# IVAHD_PRM register map
Vendor: Texas Instruments
Peripheral module from a debugger description file (folder omap4430).
Registers are 32-bit, access not given, reset 0xFF0E03 unless marked. A register's access mark holds for its fields unless they carry their own. Offsets are as the file gives them; lines under a group give offsets from that group; [hi:lo] are bit positions; {n}, {i} and the like mark numbered series; 'fields as' and 'values as' point back to an identical list; <NAME> marks a mode.

## IVAHD_PRM
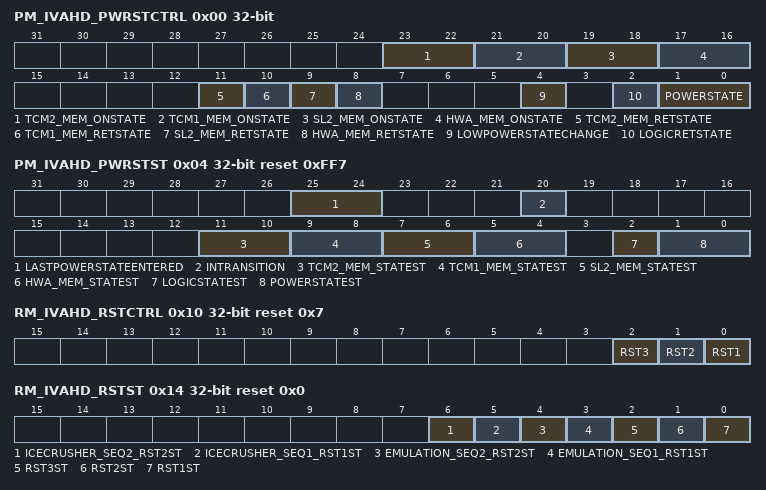
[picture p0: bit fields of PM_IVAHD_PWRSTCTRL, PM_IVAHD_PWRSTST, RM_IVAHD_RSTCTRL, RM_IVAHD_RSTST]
0x00 PM_IVAHD_PWRSTCTRL — This register controls the IVAHD power state to reach upon a domain sleep transition
  [23:22] TCM2_MEM_ONSTATE — TCM2 memory state when domain is ON. (access R Rreturns1s)
    3=TCM2_MEM_ONSTATE_3_r (Memory bank is on when the domain is ON.)
  [21:20] TCM1_MEM_ONSTATE — TCM1 memory state when domain is ON. (access R Rreturns1s)
    3=TCM1_MEM_ONSTATE_3_r (Memory bank is on when the domain is ON.)
  [19:18] SL2_MEM_ONSTATE — SL2 memory state when domain is ON. (access R Rreturns1s)
    3=SL2_MEM_ONSTATE_3_r (Memory bank is on when the domain is ON.)
  [17:16] HWA_MEM_ONSTATE — HWA memory state when domain is ON. (access R Rreturns1s)
    3=HWA_MEM_ONSTATE_3_r (Memory bank is on when the domain is ON.)
  [11] TCM2_MEM_RETSTATE rw — TCM2 memory state when domain is RETENTION.
    0=Memory bank is off when the domain is in the RETENTION state; 1=Memory bank is retained when domain is in RETENTION state
  [10] TCM1_MEM_RETSTATE rw — TCM1 memory state when domain is RETENTION.
    values as TCM2_MEM_RETSTATE
  [9] SL2_MEM_RETSTATE rw — SL2 memory state when domain is RETENTION.
    values as TCM2_MEM_RETSTATE
  [8] HWA_MEM_RETSTATE ro — HWA memory state when domain is RETENTION.
    0=HWA_MEM_RETSTATE_0_r (Memory bank is off when the domain is in the RETENTION state.)
  [4] LOWPOWERSTATECHANGE — Power state change request when domain has already performed a sleep transition. Allows going into deeper low power state without waking up the power domain. (access RW WSpecial)
    0=Do not request a low power state change; 1=Request a low power state change. This bit is automatically cleared when the power state is effectively changed or when power state is ON.
  [2] LOGICRETSTATE ro — Logic state when power domain is RETENTION
    0=LOGICRETSTATE_0_r (Whole logic is off when the domain is in RETENTION state.)
  [1:0] POWERSTATE rw — Power state control
    0=OFF state; 1=RETENTION state; 2=INACTIVE state; 3=ON State
0x04 PM_IVAHD_PWRSTST reset 0xFF7 — This register provides a status on the current IVAHD power domain state. [warm reset insensitive]
  [25:24] LASTPOWERSTATEENTERED — Last low power state entered. Set to 0x3 upon write of the same only. This register is intended for debug purpose only. (access RW W1toSet)
    3=LASTPOWERSTATEENTERED_3_r (Power domain was previously ON-ACTIVE); 2=LASTPOWERSTATEENTERED_2_r (Power domain was previously ON-INACTIVE); 1=LASTPOWERSTATEENTERED_1_r (Power domain was previously in RETENTION); 0=LASTPOWERSTATEENTERED_0_r (Power domain was previously OFF)
  [20] INTRANSITION ro — Domain transition status
    0=INTRANSITION_0_r (No ongoing transition on power domain); 1=INTRANSITION_1_r (Power domain transition is in progress.)
  [11:10] TCM2_MEM_STATEST ro — TCM2 memory state status
    0=TCM2_MEM_STATEST_0_r (Memory is OFF); 1=TCM2_MEM_STATEST_1_r (Memory is RETENTION); 2=TCM2_MEM_STATEST_2_r (Reserved); 3=TCM2_MEM_STATEST_3_r (Memory is ON)
  [9:8] TCM1_MEM_STATEST ro — TCM1 memory state status
    0=TCM1_MEM_STATEST_0_r (Memory is OFF); 1=TCM1_MEM_STATEST_1_r (Memory is RETENTION); 2=TCM1_MEM_STATEST_2_r (Reserved); 3=TCM1_MEM_STATEST_3_r (Memory is ON)
  [7:6] SL2_MEM_STATEST ro — SL2 memory state status
    0=SL2_MEM_STATEST_0_r (Memory is OFF); 1=SL2_MEM_STATEST_1_r (Memory is RETENTION); 2=SL2_MEM_STATEST_2_r (Reserved); 3=SL2_MEM_STATEST_3_r (Memory is ON)
  [5:4] HWA_MEM_STATEST ro — HWA memory state status
    0=HWA_MEM_STATEST_0_r (Memory is OFF); 1=HWA_MEM_STATEST_1_r (Memory is RETENTION); 2=HWA_MEM_STATEST_2_r (Reserved); 3=HWA_MEM_STATEST_3_r (Memory is ON)
  [2] LOGICSTATEST ro — Logic state status
    0=LOGICSTATEST_0_r (Logic in domain is OFF); 1=LOGICSTATEST_1_r (Logic in domain is ON)
  [1:0] POWERSTATEST ro — Current power state status
    0=POWERSTATEST_0_r (Power domain is OFF); 1=POWERSTATEST_1_r (Power domain is in RETENTION); 2=POWERSTATEST_2_r (Power domain is ON-INACTIVE); 3=POWERSTATEST_3_r (Power domain is ON-ACTIVE)
0x10 RM_IVAHD_RSTCTRL access per field reset 0x7 — This register controls the release of the IVAHD sub-system resets.
  [2] RST3 rw — IVAHD logic and SL2 reset control
    0=Reset is cleared for the IVAHD logic and SL2; 1=Reset is asserted for IVAHD logic and SL2
  [1] RST2 rw — IVAHD Sequencer2 reset control
    0=Reset is cleared for IVAHD Sequencer CPU2; 1=Reset is asserted for IVAHD Sequencer CPU2
  [0] RST1 rw — IVAHD sequencer1 reset control
    0=Reset is cleared for the IVAHD Sequencer CPU1; 1=Reset is asserted for the IVAHD sequencer CPU1
0x14 RM_IVAHD_RSTST reset 0x0 — This register logs the different reset sources of the IVAHD domain. Each bit is set upon release of the domain reset signal. Must be cleared by software. [warm reset insensitive]
  [6] ICECRUSHER_SEQ2_RST2ST — Sequencer2 CPU has been reset due to IVAHD ICECRUSHER2 reset event (access RW W1toClr)
    0=No icecrusher reset; 1=Sequencer2 has been reset upon icecrusher reset
  [5] ICECRUSHER_SEQ1_RST1ST — Sequencer1 CPU has been reset due to IVAHD ICECRUSHER1 reset event (access RW W1toClr)
    0=No icecrusher reset; 1=Sequencer1 has been reset upon icecrusher reset
  [4] EMULATION_SEQ2_RST2ST — (access RW W1toClr)
    0=No emulation reset; 1=Sequencer2 has been reset upon emulation reset
  [3] EMULATION_SEQ1_RST1ST — Sequencer1 CPU has been reset due to emulation reset source, that is, assert reset command initiated by the icepick module (access RW W1toClr)
    0=No emulation reset; 1=Sequencer1 has been reset upon emulation reset
  [2] RST3ST — IVAHD logic and SL2 software reset (access RW W1toClr)
    0=No software reset occured; 1=IVAHD logic and SL2 has been reset upon software reset
  [1] RST2ST — IVAHD Sequencer2 CPU software reset (access RW W1toClr)
    0=No software reset occured; 1=Sequencer2 has been reset upon software reset
  [0] RST1ST — IVAHD Sequencer1 CPU software reset (access RW W1toClr)
    0=No software reset occured; 1=Sequencer1 has been reset upon software reset
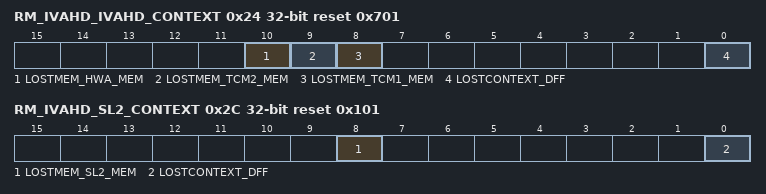
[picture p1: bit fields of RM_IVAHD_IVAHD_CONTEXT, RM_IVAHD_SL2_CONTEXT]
0x24 RM_IVAHD_IVAHD_CONTEXT reset 0x701 — This register contains dedicated IVAHD context statuses. [warm reset insensitive]
  [all] fields
    0=Context has been maintained; 1=Context has been lost
  [10] LOSTMEM_HWA_MEM — Specify if memory-based context in HWA_MEM memory bank has been lost due to a previous power transition or other reset source. (access RW W1toClr)
  [9] LOSTMEM_TCM2_MEM — Specify if memory-based context in TCM2_MEM memory bank has been lost due to a previous power transition or other reset source. (access RW W1toClr)
  [8] LOSTMEM_TCM1_MEM — Specify if memory-based context in TCM1_MEM memory bank has been lost due to a previous power transition or other reset source. (access RW W1toClr)
  [0] LOSTCONTEXT_DFF — Specify if DFF-based context has been lost due to a previous power transition or other reset source. (set upon assertion of IVAHD_RST signal) (access RW W1toClr)
0x2C RM_IVAHD_SL2_CONTEXT reset 0x101 — This register contains dedicated SL2 context statuses. [warm reset insensitive]
  [8] LOSTMEM_SL2_MEM — Specify if memory-based context in SL2_MEM memory bank has been lost due to a previous power transition or other reset source. (access RW W1toClr)
    0=Context has been maintained; 1=Context has been lost
  [0] LOSTCONTEXT_DFF — Specify if DFF-based context has been lost due to a previous power transition or other reset source. (set upon assertion of IVAHD_RST signal) (access RW W1toClr)
    0=Context has been maintained; 1=Context has been lost
